VERSION "43"

NS_ :

BS_:

BU_: Lorem Ipsum Dolor

BO_ 256 Foo: 4 Lorem
 SG_ Voltage : 16|16@1+ (0.000976562,0) [0E-009|63.9990234375] "V" Vector__XXX
 SG_ Current : 0|16@1- (0.0625,0) [-2048|2047.9375] "A" Vector__XXX

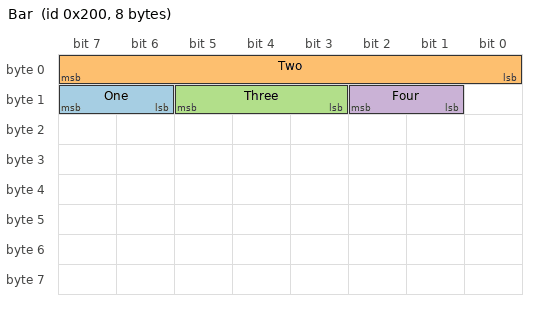
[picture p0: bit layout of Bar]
BO_ 512 Bar: 8 Ipsum
 SG_ One : 15|2@0+ (1,0) [0|3] "" Dolor
 SG_ Two : 7|8@0+ (0.39,0) [0.00|100] "%" Dolor
 SG_ Three : 13|3@0+ (1,0) [0|7] "" Dolor
 SG_ Four : 10|2@0+ (1,0) [0|3] "" Dolor

BO_ 1024 Dolor: 8 Vector__XXX
 SG_ Five : 0|4@1+ (10.23,0) [0.00|100.30] "" Vector__XXX

VAL_ 512 Three 0 "OFF" 1 "ON" 2 "ONER" 3 "ONEST";
VAL_ 512 Four 0 "Off" 1 "On" 2 "Oner" 3 "Onest";

VAL_ 1024 Five 2048 "Dolor";
